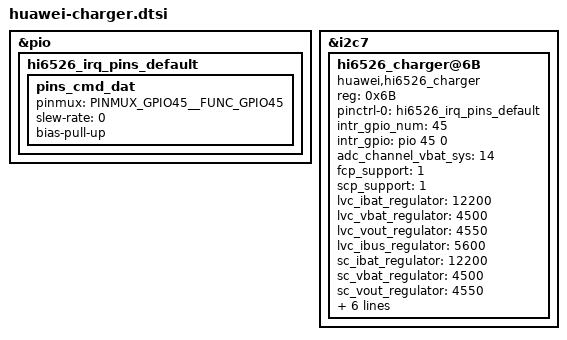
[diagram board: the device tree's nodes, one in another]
#include "../huawei_charger/mt6853_chl_22p5w_huawei_charger.dtsi"

&pio {
	hi6526_irq_pins_default: hi6526_irq_pins_default {
		pins_cmd_dat {
			pinmux = <PINMUX_GPIO45__FUNC_GPIO45>;
			slew-rate = <0>;
			bias-pull-up;
		};
	};
};

&i2c7 {
			hi6526_charger@6B{
				compatible = "huawei,hi6526_charger";
				reg = <0x6B>;
				pinctrl-names = "default";
				pinctrl-0 = <&hi6526_irq_pins_default>;
				intr_gpio_num = <45>; /* direct defined GPIO num */
				intr_gpio = <&pio 45 0>;
				adc_channel_vbat_sys = <14>;
				fcp_support = <1>;
				scp_support = <1>;
				lvc_ibat_regulator = <12200>;
				lvc_vbat_regulator = <4500>;
				lvc_vout_regulator = <4550>;
				lvc_ibus_regulator = <5600>;
				sc_ibat_regulator = <12200>;
				sc_vbat_regulator = <4500>;
				sc_vout_regulator = <4550>;
				sc_ibus_regulator = <5600>;
				lvc_vusb2vbus_drop_en = <1>;
				sc_vusb2vbus_drop_en = <1>;
				bat_comp = <30>;
				vclamp = <90>;
				r_coul_mohm = <2>;
				status = "ok";
			};
};
